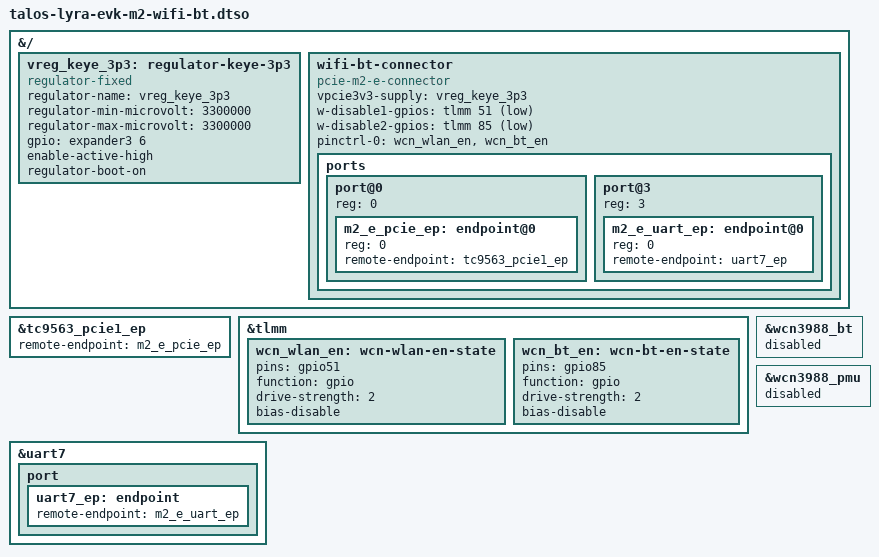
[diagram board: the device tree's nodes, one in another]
// SPDX-License-Identifier: BSD-3-Clause
/*
 * Copyright (c) Qualcomm Technologies, Inc. and/or its subsidiaries.
 */

/dts-v1/;
/plugin/;

#include <dt-bindings/gpio/gpio.h>

/*
 * M.2 Key-E QCC2072 Wi-Fi/Bluetooth card on Talos Lyra EVK.
 *
 * Wi-Fi is connected via the PCIe1 downstream port of the QPS615 (TC9563)
 * PCIe switch and Bluetooth via SoC UART7. The on-board WCN3988 Bluetooth
 * described in the base DT shares UART7 with the slot, so it is disabled
 * here.
 */

&{/} {
	vreg_keye_3p3: regulator-keye-3p3 {
		compatible = "regulator-fixed";
		regulator-name = "vreg_keye_3p3";
		regulator-min-microvolt = <3300000>;
		regulator-max-microvolt = <3300000>;
		gpio = <&expander3 6 GPIO_ACTIVE_HIGH>;
		enable-active-high;
		regulator-boot-on;
	};

	wifi-bt-connector {
		compatible = "pcie-m2-e-connector";
		vpcie3v3-supply = <&vreg_keye_3p3>;

		w-disable1-gpios = <&tlmm 51 GPIO_ACTIVE_LOW>;
		w-disable2-gpios = <&tlmm 85 GPIO_ACTIVE_LOW>;

		pinctrl-0 = <&wcn_wlan_en>, <&wcn_bt_en>;
		pinctrl-names = "default";

		ports {
			#address-cells = <1>;
			#size-cells = <0>;

			port@0 {
				reg = <0>;
				#address-cells = <1>;
				#size-cells = <0>;

				m2_e_pcie_ep: endpoint@0 {
					reg = <0>;
					remote-endpoint = <&tc9563_pcie1_ep>;
				};
			};

			port@3 {
				reg = <3>;
				#address-cells = <1>;
				#size-cells = <0>;

				m2_e_uart_ep: endpoint@0 {
					reg = <0>;
					remote-endpoint = <&uart7_ep>;
				};
			};
		};
	};
};

&tc9563_pcie1_ep {
	remote-endpoint = <&m2_e_pcie_ep>;
};

&tlmm {
	wcn_wlan_en: wcn-wlan-en-state {
		pins = "gpio51";
		function = "gpio";
		drive-strength = <2>;
		bias-disable;
	};

	wcn_bt_en: wcn-bt-en-state {
		pins = "gpio85";
		function = "gpio";
		drive-strength = <2>;
		bias-disable;
	};
};

&wcn3988_bt {
	status = "disabled";
};

&uart7 {
	port {
		uart7_ep: endpoint {
			remote-endpoint = <&m2_e_uart_ep>;
		};
	};
};

/* The on-board WCN3988 PMU is not used with the M.2 card */
&wcn3988_pmu {
	status = "disabled";
};
